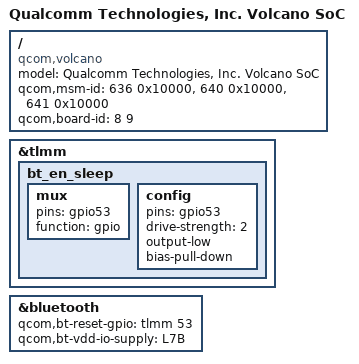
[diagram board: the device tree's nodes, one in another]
/dts-v1/;
/plugin/;

#include "volcano-wcn6450-bt.dtsi"

/ {
        model = "Qualcomm Technologies, Inc. Volcano SoC";
        compatible = "qcom,volcano";
        qcom,msm-id = <636 0x10000>, <640 0x10000>, <641 0x10000>;
        qcom,board-id = <8 9>;
};

&tlmm {
	bt_en_sleep: bt_en_sleep {
		mux {
			pins = "gpio53";
			function = "gpio";
		};

		config {
			pins = "gpio53";
			drive-strength = <2>;
			output-low;
			bias-pull-down;
		};
	};
};

&bluetooth {
	qcom,bt-reset-gpio = <&tlmm 53 0>; /* BT_EN */
	qcom,bt-vdd-io-supply = <&L7B>;  /* IO */
};

